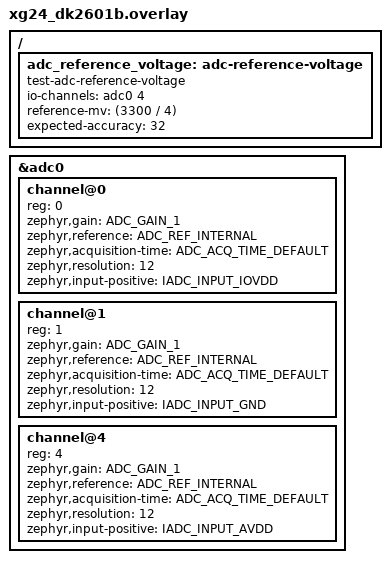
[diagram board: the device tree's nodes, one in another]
/*
 * SPDX-License-Identifier: Apache-2.0
 *
 * Copyright (c) 2023 Antmicro <www.antmicro.com>
 */

#include "dt-bindings/adc/silabs-adc.h"

&adc0 {
	#address-cells = <1>;
	#size-cells = <0>;

	channel@0 {
		reg = <0>;
		zephyr,gain = "ADC_GAIN_1";
		zephyr,reference = "ADC_REF_INTERNAL";
		zephyr,acquisition-time = <ADC_ACQ_TIME_DEFAULT>;
		zephyr,resolution = <12>;
		zephyr,input-positive = <IADC_INPUT_IOVDD>;
	};

	channel@1 {
		reg = <1>;
		zephyr,gain = "ADC_GAIN_1";
		zephyr,reference = "ADC_REF_INTERNAL";
		zephyr,acquisition-time = <ADC_ACQ_TIME_DEFAULT>;
		zephyr,resolution = <12>;
		zephyr,input-positive = <IADC_INPUT_GND>;
	};

	channel@4 {
		reg = <4>;
		zephyr,gain = "ADC_GAIN_1";
		zephyr,reference = "ADC_REF_INTERNAL";
		zephyr,acquisition-time = <ADC_ACQ_TIME_DEFAULT>;
		zephyr,resolution = <12>;
		zephyr,input-positive = <IADC_INPUT_AVDD>;
	};
};

/ {
	adc_reference_voltage: adc-reference-voltage {
		compatible = "test-adc-reference-voltage";
		io-channels = <&adc0 4>;
		reference-mv = <(3300 / 4)>;
		expected-accuracy = <32>;
	};
};
